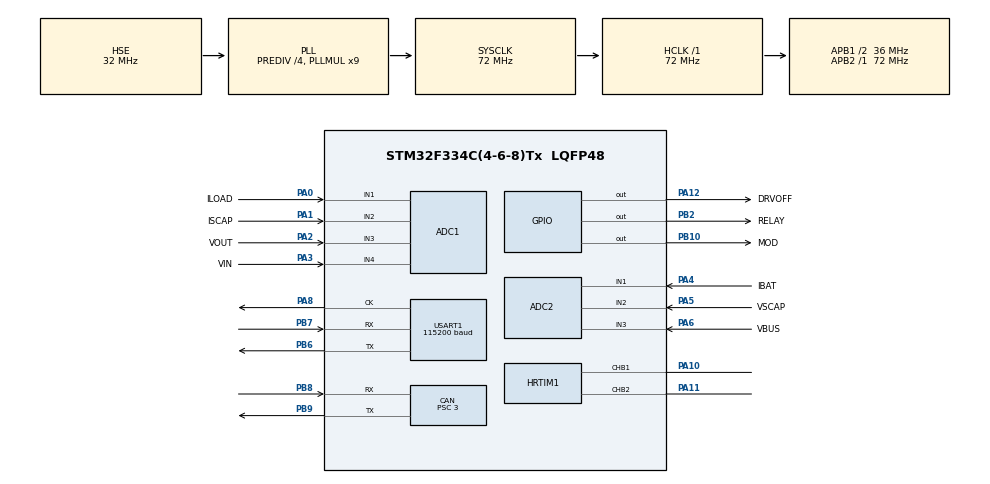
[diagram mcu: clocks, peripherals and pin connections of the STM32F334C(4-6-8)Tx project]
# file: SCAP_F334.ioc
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ADC1.Channel-4\#ChannelRegularConversion=ADC_CHANNEL_2
ADC1.Channel-5\#ChannelRegularConversion=ADC_CHANNEL_3
ADC1.Channel-6\#ChannelRegularConversion=ADC_CHANNEL_4
ADC1.DMAContinuousRequests=ENABLE
ADC1.ExternalTrigConv=ADC_EXTERNALTRIGCONVHRTIM_TRG1
ADC1.ExternalTrigConvEdge=ADC_EXTERNALTRIGCONVEDGE_RISING
ADC1.ExternalTrigInjecConv=ADC_EXTERNALTRIGINJECCONV_HRTIM_TRG2
ADC1.InjNumberOfConversion=1
ADC1.InjectedChannel-7\#ChannelInjectedConversion=ADC_CHANNEL_1
ADC1.InjectedOffset-7\#ChannelInjectedConversion=0
ADC1.InjectedOffsetNumber-7\#ChannelInjectedConversion=ADC_OFFSET_NONE
ADC1.InjectedRank-7\#ChannelInjectedConversion=1
ADC1.InjectedSamplingTime-7\#ChannelInjectedConversion=ADC_SAMPLETIME_1CYCLE_5
ADC1.InjectedSamplingTimeOPAMP-7\#ChannelInjectedConversion=ADC_SAMPLETIME_61CYCLES_5
ADC1.NbrOfConversion=3
ADC1.NbrOfConversionFlag=1
ADC1.Offset-4\#ChannelRegularConversion=0
ADC1.Offset-5\#ChannelRegularConversion=0
ADC1.Offset-6\#ChannelRegularConversion=0
ADC1.OffsetNumber-4\#ChannelRegularConversion=ADC_OFFSET_NONE
ADC1.OffsetNumber-5\#ChannelRegularConversion=ADC_OFFSET_NONE
ADC1.OffsetNumber-6\#ChannelRegularConversion=ADC_OFFSET_NONE
ADC1.Rank-4\#ChannelRegularConversion=1
ADC1.Rank-5\#ChannelRegularConversion=2
ADC1.Rank-6\#ChannelRegularConversion=3
ADC1.Rank1_Channel=ADC_CHANNEL_1
ADC1.SamplingTime-4\#ChannelRegularConversion=ADC_SAMPLETIME_19CYCLES_5
ADC1.SamplingTime-5\#ChannelRegularConversion=ADC_SAMPLETIME_19CYCLES_5
ADC1.SamplingTime-6\#ChannelRegularConversion=ADC_SAMPLETIME_19CYCLES_5
ADC1.SamplingTimeOPAMP-4\#ChannelRegularConversion=ADC_SAMPLETIME_61CYCLES_5
ADC1.SamplingTimeOPAMP-5\#ChannelRegularConversion=ADC_SAMPLETIME_61CYCLES_5
ADC1.SamplingTimeOPAMP-6\#ChannelRegularConversion=ADC_SAMPLETIME_61CYCLES_5
ADC1.SubFamily=STM32F334x8
ADC1.master=1
ADC2.Channel-3\#ChannelRegularConversion=ADC_CHANNEL_2
ADC2.Channel-4\#ChannelRegularConversion=ADC_CHANNEL_3
ADC2.DMAContinuousRequests=ENABLE
ADC2.ExternalTrigConv=ADC_EXTERNALTRIGCONVHRTIM_TRG1
ADC2.ExternalTrigConvEdge=ADC_EXTERNALTRIGCONVEDGE_RISING
ADC2.ExternalTrigInjecConv=ADC_EXTERNALTRIGINJECCONV_HRTIM_TRG2
ADC2.InjNumberOfConversion=1
ADC2.InjectedChannel-5\#ChannelInjectedConversion=ADC_CHANNEL_1
ADC2.InjectedOffset-5\#ChannelInjectedConversion=0
ADC2.InjectedOffsetNumber-5\#ChannelInjectedConversion=ADC_OFFSET_NONE
ADC2.InjectedRank-5\#ChannelInjectedConversion=1
ADC2.InjectedSamplingTime-5\#ChannelInjectedConversion=ADC_SAMPLETIME_1CYCLE_5
ADC2.InjectedSamplingTimeOPAMP-5\#ChannelInjectedConversion=ADC_SAMPLETIME_61CYCLES_5
ADC2.NbrOfConversion=2
ADC2.NbrOfConversionFlag=1
ADC2.Offset-3\#ChannelRegularConversion=0
ADC2.Offset-4\#ChannelRegularConversion=0
ADC2.OffsetNumber-3\#ChannelRegularConversion=ADC_OFFSET_NONE
ADC2.OffsetNumber-4\#ChannelRegularConversion=ADC_OFFSET_NONE
ADC2.Rank-3\#ChannelRegularConversion=1
ADC2.Rank-4\#ChannelRegularConversion=2
ADC2.Rank1_Channel=ADC_CHANNEL_1
ADC2.SamplingTime-3\#ChannelRegularConversion=ADC_SAMPLETIME_19CYCLES_5
ADC2.SamplingTime-4\#ChannelRegularConversion=ADC_SAMPLETIME_19CYCLES_5
ADC2.SamplingTimeOPAMP-3\#ChannelRegularConversion=ADC_SAMPLETIME_61CYCLES_5
ADC2.SamplingTimeOPAMP-4\#ChannelRegularConversion=ADC_SAMPLETIME_61CYCLES_5
ADC2.SubFamily=STM32F334x8
CAN.BS1=CAN_BS1_7TQ
CAN.BS2=CAN_BS2_4TQ
CAN.CalculateBaudRate=999999
CAN.CalculateTimeBit=1000
CAN.CalculateTimeQuantum=83.33333333333334
CAN.NART=ENABLE
CAN.Prescaler=3
Dma.ADC1.0.Direction=DMA_PERIPH_TO_MEMORY
Dma.ADC1.0.Instance=DMA1_Channel1
Dma.ADC1.0.MemDataAlignment=DMA_MDATAALIGN_HALFWORD
Dma.ADC1.0.MemInc=DMA_MINC_ENABLE
Dma.ADC1.0.Mode=DMA_CIRCULAR
Dma.ADC1.0.PeriphDataAlignment=DMA_PDATAALIGN_HALFWORD
Dma.ADC1.0.PeriphInc=DMA_PINC_DISABLE
Dma.ADC1.0.Priority=DMA_PRIORITY_VERY_HIGH
Dma.ADC2.1.Direction=DMA_PERIPH_TO_MEMORY
Dma.ADC2.1.Instance=DMA1_Channel2
Dma.ADC2.1.MemDataAlignment=DMA_MDATAALIGN_HALFWORD
Dma.ADC2.1.MemInc=DMA_MINC_ENABLE
Dma.ADC2.1.Mode=DMA_CIRCULAR
Dma.ADC2.1.PeriphDataAlignment=DMA_PDATAALIGN_HALFWORD
Dma.ADC2.1.PeriphInc=DMA_PINC_DISABLE
Dma.ADC2.1.Priority=DMA_PRIORITY_HIGH
Dma.Request0=ADC1
Dma.Request1=ADC2
HRTIM1.ADCTrigger1_Source1=HRTIM_ADCTRIGGEREVENT13_TIMERB_CMP2
HRTIM1.ADCTrigger2_Source1=HRTIM_ADCTRIGGEREVENT24_TIMERB_CMP3
HRTIM1.ADCTrigger_Id1=HRTIM_ADCTRIGGER_1
HRTIM1.ADCTrigger_Id2=HRTIM_ADCTRIGGER_2
HRTIM1.CompareUnit1-Output_TB1TB2=HRTIM_COMPAREUNIT_1
HRTIM1.CompareUnit2-Output_TB1TB2=HRTIM_COMPAREUNIT_2
HRTIM1.CompareUnit3-Output_TB1TB2=HRTIM_COMPAREUNIT_3
HRTIM1.CompareValue1-Output_TB1TB2=46080
HRTIM1.CompareValue2-Output_TB1TB2=46080
HRTIM1.CompareValue3-Output_TB1TB2=46080
HRTIM1.DeadTimeInsertion-Output_TB1TB2=HRTIM_TIMDEADTIMEINSERTION_ENABLED
HRTIM1.FallingValue-Output_TB1TB2=50
HRTIM1.NumberADCTriggerSource1=1
HRTIM1.NumberADCTriggerSource2=1
HRTIM1.NumberResetSource1-Output_TB1TB2=1
HRTIM1.NumberSetSource1-Output_TB1TB2=1
HRTIM1.ORingUpdateSource_ADCTrigger1=HRTIM_ADCTRIGGERUPDATE_TIMER_B
HRTIM1.ORingUpdateSource_ADCTrigger2=HRTIM_ADCTRIGGERUPDATE_TIMER_B
HRTIM1.Periode_MASTER=46080
HRTIM1.Periode_TB=46080
HRTIM1.ResetOutput1_Source1-Output_TB1TB2=HRTIM_OUTPUTRESET_TIMCMP1
HRTIM1.RisingValue-Output_TB1TB2=50
HRTIM1.SetOutput1_Source1-Output_TB1TB2=HRTIM_OUTPUTSET_TIMPER
Mcu.Family=STM32F3
Mcu.Name=STM32F334C(4-6-8)Tx
Mcu.Package=LQFP48
NVIC.ADC1_2_IRQn=true\:0\:0\:false\:false\:true\:true\:false\:true
NVIC.CAN_RX0_IRQn=true\:1\:0\:true\:false\:true\:true\:true\:true
NVIC.DMA1_Channel1_IRQn=true\:0\:0\:false\:false\:true\:false\:false\:true
NVIC.PriorityGroup=NVIC_PRIORITYGROUP_4
NVIC.TIM1_TRG_COM_TIM17_IRQn=true\:1\:0\:true\:false\:true\:true\:false\:true
PA0.GPIO_Label=ILOAD
PA0.Mode=IN1-Single-Ended
PA0.Signal=ADC1_IN1
PA1.GPIO_Label=ISCAP
PA1.Mode=IN2-Single-Ended
PA1.Signal=ADC1_IN2
PA10.GPIO_Mode=GPIO_MODE_AF_PP
PA10.GPIO_PuPd=GPIO_PULLDOWN
PA10.GPIO_Speed_High_Default=GPIO_SPEED_FREQ_HIGH
PA10.Mode=Output_TB1TB2
PA10.Signal=HRTIM1_CHB1
PA11.GPIO_Mode=GPIO_MODE_AF_PP
PA11.GPIO_PuPd=GPIO_PULLDOWN
PA11.GPIO_Speed_High_Default=GPIO_SPEED_FREQ_HIGH
PA11.Mode=Output_TB1TB2
PA11.Signal=HRTIM1_CHB2
PA12.GPIO_Label=DRVOFF
PA12.GPIO_PuPd=GPIO_PULLUP
PA12.GPIO_Speed=GPIO_SPEED_FREQ_HIGH
PA12.PinState=GPIO_PIN_SET
PA12.Signal=GPIO_Output
PA13.Mode=Serial_Wire
PA13.Signal=SYS_JTMS-SWDIO
PA14.Mode=Serial_Wire
PA14.Signal=SYS_JTCK-SWCLK
PA2.GPIO_Label=VOUT
PA2.Mode=IN3-Single-Ended
PA2.Signal=ADC1_IN3
PA3.GPIO_Label=VIN
PA3.Mode=IN4-Single-Ended
PA3.Signal=ADC1_IN4
PA4.GPIO_Label=IBAT
PA4.Mode=IN1-Single-Ended
PA4.Signal=ADC2_IN1
PA5.GPIO_Label=VSCAP
PA5.Mode=IN2-Single-Ended
PA5.Signal=ADC2_IN2
PA6.GPIO_Label=VBUS
PA6.Mode=IN3-Single-Ended
PA6.Signal=ADC2_IN3
PA8.Mode=Synchronous
PA8.Signal=USART1_CK
PB10.GPIO_Label=MOD
PB10.GPIO_PuPd=GPIO_PULLUP
PB10.GPIO_Speed=GPIO_SPEED_FREQ_HIGH
PB10.Signal=GPIO_Output
PB2.GPIO_Label=RELAY
PB2.GPIO_PuPd=GPIO_PULLUP
PB2.GPIO_Speed=GPIO_SPEED_FREQ_HIGH
PB2.Signal=GPIO_Output
PB6.Mode=Synchronous
PB6.Signal=USART1_TX
PB7.Mode=Synchronous
PB7.Signal=USART1_RX
PB8.Mode=CAN_Activate
PB8.Signal=CAN_RX
PB9.Mode=CAN_Activate
PB9.Signal=CAN_TX
PF0\ /\ OSC_IN.Mode=HSE-External-Oscillator
PF0\ /\ OSC_IN.Signal=RCC_OSC_IN
PF1\ /\ OSC_OUT.Mode=HSE-External-Oscillator
PF1\ /\ OSC_OUT.Signal=RCC_OSC_OUT
ProjectManager.HeapSize=0x500
ProjectManager.StackSize=0x1000
ProjectManager.TargetToolchain=MDK-ARM V5
RCC.AHBFreq_Value=72000000
RCC.APB1CLKDivider=RCC_HCLK_DIV2
RCC.APB1Freq_Value=36000000
RCC.APB1TimFreq_Value=72000000
RCC.APB2Freq_Value=72000000
RCC.APB2TimFreq_Value=72000000
RCC.CortexFreq_Value=72000000
RCC.HCLKFreq_Value=72000000
RCC.HRTIMSelection=RCC_HRTIM1CLK_PLLCLK
RCC.HSE_VALUE=32000000
RCC.HSI_VALUE=8000000
RCC.LSE_VALUE=32768
RCC.PLLMUL=RCC_PLL_MUL9
RCC.PLLSourceVirtual=RCC_PLLSOURCE_HSE
RCC.RCC_PLLsource_Clock_Source_FROM_HSE=RCC_HSE_PREDIV_DIV4
RCC.SYSCLKFreq_VALUE=72000000
RCC.SYSCLKSourceVirtual=RCC_SYSCLKSOURCE_PLLCLK
TIM17.Period=2400-1
TIM17.Prescaler=1-1
USART1.BaudRate=115200
USART1.VirtualMode-Synchronous=VM_SYNC
VP_HRTIM1_VS_hrtimMasterTimerNoOutput.Mode=MasterTimer
VP_TIM17_VS_ClockSourceINT.Mode=Enable_Timer
board=custom

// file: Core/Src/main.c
/* USER CODE BEGIN Header */
/**
  ******************************************************************************
  * @file           : main.c
  * @brief          : Main program body
  ******************************************************************************
  * @attention
  *
  * Copyright (c) 2023 STMicroelectronics.
  * All rights reserved.
  *
  * This software is licensed under terms that can be found in the LICENSE file
  * in the root directory of this software component.
  * If no LICENSE file comes with this software, it is provided AS-IS.
  *
  ******************************************************************************
  */
/* USER CODE END Header */
#include "main.h"
#include "adc.h"
#include "can.h"
#include "dma.h"
#include "hrtim.h"
#include "tim.h"
#include "usart.h"
#include "gpio.h"

/* USER CODE BEGIN Includes */
#include "common.h"

/* USER CODE END Includes */

void SystemClock_Config(void);

int main(void)
{

  /* MCU Configuration--------------------------------------------------------*/

  /* Reset of all peripherals, Initializes the Flash interface and the Systick. */
  HAL_Init();

  /* Configure the system clock */
  SystemClock_Config();

  /* Initialize all configured peripherals */
  MX_GPIO_Init();
  MX_DMA_Init();
  MX_ADC1_Init();
  MX_ADC2_Init();
  MX_CAN_Init();
  MX_HRTIM1_Init();
  MX_USART1_Init();
  MX_TIM17_Init();
  /* USER CODE BEGIN 2 */
	CAN_Filter_Init();

	SCAP_Init();
  /* USER CODE END 2 */

  /* Infinite loop */
  while (1)
  {

    /* USER CODE BEGIN 3 */
		SCAP_Main();
  }
  /* USER CODE END 3 */
}

void SystemClock_Config(void)
{
  RCC_OscInitTypeDef RCC_OscInitStruct = {0};
  RCC_ClkInitTypeDef RCC_ClkInitStruct = {0};
  RCC_PeriphCLKInitTypeDef PeriphClkInit = {0};

  /** Initializes the RCC Oscillators according to the specified parameters
  * in the RCC_OscInitTypeDef structure.
  */
  RCC_OscInitStruct.OscillatorType = RCC_OSCILLATORTYPE_HSE;
  RCC_OscInitStruct.HSEState = RCC_HSE_ON;
  RCC_OscInitStruct.HSEPredivValue = RCC_HSE_PREDIV_DIV4;
  RCC_OscInitStruct.HSIState = RCC_HSI_ON;
  RCC_OscInitStruct.PLL.PLLState = RCC_PLL_ON;
  RCC_OscInitStruct.PLL.PLLSource = RCC_PLLSOURCE_HSE;
  RCC_OscInitStruct.PLL.PLLMUL = RCC_PLL_MUL9;
  if (HAL_RCC_OscConfig(&RCC_OscInitStruct) != HAL_OK)
  {
    Error_Handler();
  }

  /** Initializes the CPU, AHB and APB buses clocks
  */
  RCC_ClkInitStruct.ClockType = RCC_CLOCKTYPE_HCLK|RCC_CLOCKTYPE_SYSCLK
                              |RCC_CLOCKTYPE_PCLK1|RCC_CLOCKTYPE_PCLK2;
  RCC_ClkInitStruct.SYSCLKSource = RCC_SYSCLKSOURCE_PLLCLK;
  RCC_ClkInitStruct.AHBCLKDivider = RCC_SYSCLK_DIV1;
  RCC_ClkInitStruct.APB1CLKDivider = RCC_HCLK_DIV2;
  RCC_ClkInitStruct.APB2CLKDivider = RCC_HCLK_DIV1;

  if (HAL_RCC_ClockConfig(&RCC_ClkInitStruct, FLASH_LATENCY_2) != HAL_OK)
  {
    Error_Handler();
  }
  PeriphClkInit.PeriphClockSelection = RCC_PERIPHCLK_HRTIM1|RCC_PERIPHCLK_USART1
                              |RCC_PERIPHCLK_ADC12;
  PeriphClkInit.Usart1ClockSelection = RCC_USART1CLKSOURCE_PCLK1;
  PeriphClkInit.Adc12ClockSelection = RCC_ADC12PLLCLK_DIV1;
  PeriphClkInit.Hrtim1ClockSelection = RCC_HRTIM1CLK_PLLCLK;
  if (HAL_RCCEx_PeriphCLKConfig(&PeriphClkInit) != HAL_OK)
  {
    Error_Handler();
  }
}

void Error_Handler(void)
{
  __disable_irq();
  while (1)
  {
  }
}
